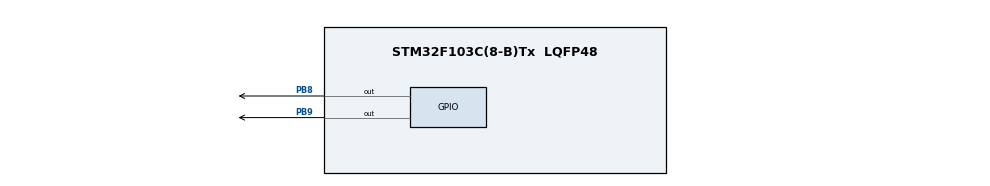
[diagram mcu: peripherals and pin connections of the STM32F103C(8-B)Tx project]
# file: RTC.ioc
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Mcu.Family=STM32F1
Mcu.Name=STM32F103C(8-B)Tx
Mcu.Package=LQFP48
NVIC.PriorityGroup=NVIC_PRIORITYGROUP_4
PA13.Mode=Serial_Wire
PA13.Signal=SYS_JTMS-SWDIO
PA14.Mode=Serial_Wire
PA14.Signal=SYS_JTCK-SWCLK
PB8.GPIO_ModeDefaultOutputPP=GPIO_MODE_OUTPUT_OD
PB8.GPIO_PuPd=GPIO_NOPULL
PB8.Signal=GPIO_Output
PB9.GPIO_ModeDefaultOutputPP=GPIO_MODE_OUTPUT_OD
PB9.GPIO_PuPd=GPIO_NOPULL
PB9.Signal=GPIO_Output
PC14-OSC32_IN.Mode=LSE-External-Oscillator
PC14-OSC32_IN.Signal=RCC_OSC32_IN
PC15-OSC32_OUT.Mode=LSE-External-Oscillator
PC15-OSC32_OUT.Signal=RCC_OSC32_OUT
PD0-OSC_IN.Mode=HSE-External-Oscillator
PD0-OSC_IN.Signal=RCC_OSC_IN
PD1-OSC_OUT.Mode=HSE-External-Oscillator
PD1-OSC_OUT.Signal=RCC_OSC_OUT
ProjectManager.HeapSize=0x200
ProjectManager.StackSize=0x400
ProjectManager.TargetToolchain=STM32CubeIDE
RCC.APB1Freq_Value=8000000
RCC.APB2Freq_Value=8000000
RCC.RTCClockSelection=RCC_RTCCLKSOURCE_LSE
RTC.Date=11
RTC.Format=RTC_FORMAT_BIN
RTC.Hours=20
RTC.Month=RTC_MONTH_APRIL
RTC.WeekDay=RTC_WEEKDAY_SATURDAY
RTC.Year=26
VP_RTC_VS_RTC_Activate.Mode=RTC_Enabled
VP_RTC_VS_RTC_Calendar.Mode=RTC_Calendar
board=custom

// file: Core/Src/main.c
/* USER CODE BEGIN Header */
/**
  ******************************************************************************
  * @file           : main.c
  * @brief          : Main program body
  ******************************************************************************
  * @attention
  *
  * Copyright (c) 2026 STMicroelectronics.
  * All rights reserved.
  *
  * This software is licensed under terms that can be found in the LICENSE file
  * in the root directory of this software component.
  * If no LICENSE file comes with this software, it is provided AS-IS.
  *
  ******************************************************************************
  */
/* USER CODE END Header */
#include "main.h"
#include "rtc.h"
#include "gpio.h"

/* USER CODE BEGIN PV */
RTC_DateTypeDef RTC_Date;
RTC_TimeTypeDef RTC_Time;
/* USER CODE END PV */

void SystemClock_Config(void);

int main(void)
{

  /* MCU Configuration--------------------------------------------------------*/

  /* Reset of all peripherals, Initializes the Flash interface and the Systick. */
  HAL_Init();

  /* Configure the system clock */
  SystemClock_Config();

  /* Initialize all configured peripherals */
  MX_GPIO_Init();
  MX_RTC_Init();

  /* Infinite loop */
  /* USER CODE BEGIN WHILE */
	OLED_Init();
//PC13小灯亮是因为使用了外部检测，想关掉，就找到MX_RTC_Init函数里的hrtc.Init.OutPut = RTC_OUTPUTSOURCE_ALARM;，把这个变量赋值为RTC_OUTPUTSOURCE_NONE即可

	OLED_ShowString(1, 1, "Date:20  -  -  ");
	OLED_ShowString(2, 1, "Time:  :  :  ");
	OLED_ShowString(3, 1, "CNT:");

  while (1)
  {
	  HAL_RTC_GetDate(&hrtc, &RTC_Date, RTC_FORMAT_BIN);
	  HAL_RTC_GetTime(&hrtc, &RTC_Time, RTC_FORMAT_BIN);

	  OLED_ShowNum(1, 8, RTC_Date.Year, 2);
	  OLED_ShowNum(1, 11, RTC_Date.Month, 2);
	  OLED_ShowNum(1, 14, RTC_Date.Date, 2);
	  OLED_ShowNum(2, 6, RTC_Time.Hours, 2);
	  OLED_ShowNum(2, 9, RTC_Time.Minutes, 2);
	  OLED_ShowNum(2, 12, RTC_Time.Seconds, 2);

	  OLED_ShowNum(3, 6, RTC_ReadTimeCounter(&hrtc), 10);
    /* USER CODE END WHILE */

  }
}

void SystemClock_Config(void)
{
  RCC_OscInitTypeDef RCC_OscInitStruct = {0};
  RCC_ClkInitTypeDef RCC_ClkInitStruct = {0};
  RCC_PeriphCLKInitTypeDef PeriphClkInit = {0};

  /** Initializes the RCC Oscillators according to the specified parameters
  * in the RCC_OscInitTypeDef structure.
  */
  RCC_OscInitStruct.OscillatorType = RCC_OSCILLATORTYPE_HSI|RCC_OSCILLATORTYPE_LSE;
  RCC_OscInitStruct.LSEState = RCC_LSE_ON;
  RCC_OscInitStruct.HSIState = RCC_HSI_ON;
  RCC_OscInitStruct.HSICalibrationValue = RCC_HSICALIBRATION_DEFAULT;
  RCC_OscInitStruct.PLL.PLLState = RCC_PLL_NONE;
  if (HAL_RCC_OscConfig(&RCC_OscInitStruct) != HAL_OK)
  {
    Error_Handler();
  }

  /** Initializes the CPU, AHB and APB buses clocks
  */
  RCC_ClkInitStruct.ClockType = RCC_CLOCKTYPE_HCLK|RCC_CLOCKTYPE_SYSCLK
                              |RCC_CLOCKTYPE_PCLK1|RCC_CLOCKTYPE_PCLK2;
  RCC_ClkInitStruct.SYSCLKSource = RCC_SYSCLKSOURCE_HSI;
  RCC_ClkInitStruct.AHBCLKDivider = RCC_SYSCLK_DIV1;
  RCC_ClkInitStruct.APB1CLKDivider = RCC_HCLK_DIV1;
  RCC_ClkInitStruct.APB2CLKDivider = RCC_HCLK_DIV1;

  if (HAL_RCC_ClockConfig(&RCC_ClkInitStruct, FLASH_LATENCY_0) != HAL_OK)
  {
    Error_Handler();
  }
  PeriphClkInit.PeriphClockSelection = RCC_PERIPHCLK_RTC;
  PeriphClkInit.RTCClockSelection = RCC_RTCCLKSOURCE_LSE;
  if (HAL_RCCEx_PeriphCLKConfig(&PeriphClkInit) != HAL_OK)
  {
    Error_Handler();
  }
}

void Error_Handler(void)
{
  __disable_irq();
  while (1)
  {
  }
}
